VERSION "1.0.0"

NS_ :

BS_:

BU_: DBG DRIVER IO MOTOR SENSOR

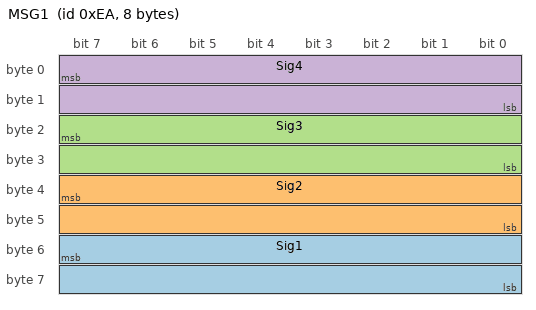
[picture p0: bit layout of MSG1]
BO_ 234 MSG1: 8 Vector__XXX
 SG_ Sig1 : 55|16@0- (0.1,0) [-3276.8|-3276.7] "C" Vector__XXX
 SG_ Sig2 : 39|16@0- (0.1,0) [-3276.8|-3276.7] "C" Vector__XXX
 SG_ Sig3 : 23|16@0- (10,0) [-3276.8|-3276.7] "C" Vector__XXX
 SG_ Sig4 : 7|16@0- (1,-10) [0|32767] "" Vector__XXX
